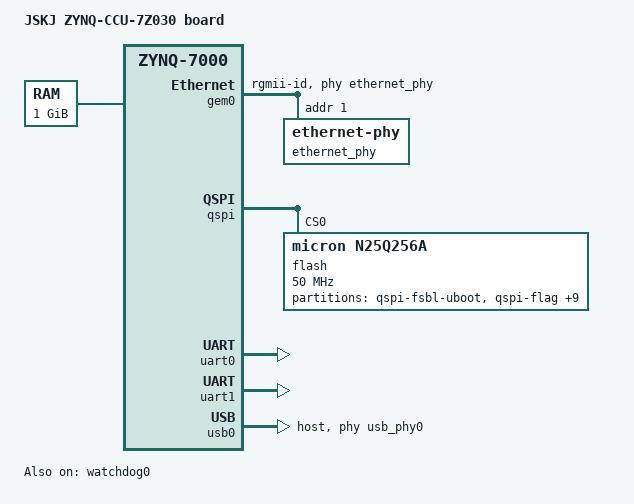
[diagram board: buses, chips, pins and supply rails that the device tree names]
/*
 * CAUTION: This file is automatically generated by Xilinx.
 * Version:  
 * Today is: Thu Jul 18 09:45:21 2024
 */

/dts-v1/;
#include "zynq-7000.dtsi"

/ {
	model = "JSKJ ZYNQ-CCU-7Z030 board";
	compatible = "xlnx,zynq-zc706", "xlnx,zynq-7000";

	aliases {
		ethernet0 = &gem0;
		serial0 = &uart0;
		spi0 = &qspi;
	};

	memory@0 {
		device_type = "memory";
		reg = <0x0 0x40000000>;
	};

	chosen {
		bootargs = "";
		stdout-path = "serial0:115200n8";
	};

	usb_phy0: phy0@e0002000 {
		compatible = "ulpi-phy";
		#phy-cells = <0>;
		reg = <0xe0002000 0x1000>;
		view-port = <0x0170>;
		drv-vbus;
	};
	
};

&clkc {
	fclk-enable = <0x1>;
	ps-clk-frequency = <33333333>;
};

&gem0 {
	status = "okay";
	phy-mode = "rgmii-id";
	phy-handle = <&ethernet_phy>;
	local-mac-address = [00 0a 35 00 00 00];
	ethernet_phy: ethernet-phy@1 {
		reg = <1>;
		device_type = "ethernet-phy";
	};
};

&qspi {
	u-boot,dm-pre-reloc;
	status = "okay";
	is-dual = <0>;
	num-cs = <1>;
	flash@0 {
		//compatible = "micron,n25q256a", "jedec,spi-nor";
		compatible = "micron,n25q256a";
		reg = <0x0>;
		spi-tx-bus-width = <4>;
		spi-rx-bus-width = <4>;
		spi-max-frequency = <50000000>;
		#address-cells = <1>;
		#size-cells = <1>;
		partition@0 {
			label = "qspi-fsbl-uboot";
			reg = <0x0 0x1D0000>;
		};
		partition@1D0000 {
			label = "qspi-flag";
			reg = <0x1D0000 0x10000>;//64KB
		};
		partition@1E0000 {
			label = "qspi-env";
			reg = <0x1E0000 0x10000>;//64KB
		};
		partition@200000 {
			label = "qspi-linux-a";
			reg = <0x200000 0x400000>;
		};
		partition@600000 {
			label = "qspi-devicetree-a";
			reg = <0x600000 0x10000>;
		};
		partition@610000 {
			label = "qspi-linux-b";
			reg = <0x610000 0x400000>;
		};
		partition@A10000 {
			label = "qspi-devicetree-b";
			reg = <0xA10000 0x10000>;
		};
		partition@A20000 {
			label = "qspi-bitstream-a";
			reg = <0xA20000 0x400000>;
		};
		partition@E20000 {
			label = "qspi-bitstream-b";
			reg = <0xE20000 0x400000>;
		};
		partition@1220000 {
			label = "qspi-rootfs-a";
			reg = <0x1220000 0x680000>;
		};
		partition@18A0000 {
			label = "qspi-rootfs-b";
			reg = <0x18A0000 0x680000>;
		};
	};
};


&uart0 {
	cts-override ;
	device_type = "serial";
	port-number = <0>;
	status = "okay";
	u-boot,dm-pre-reloc;
};

&uart1 {
	u-boot,dm-pre-reloc;
	status = "okay";
};

&usb0 {
	status = "okay";
	phy_type = "ulpi";
	dr_mode = "host";
	usb-phy = <&usb_phy0>;
};

&watchdog0 {
    status = "okay";
    reset-on-timeout;
    timeout-sec = <60>;
};
